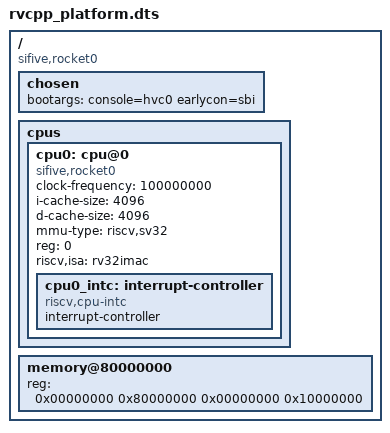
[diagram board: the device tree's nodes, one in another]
/dts-v1/;
/ {
	#address-cells = <2>;
	#size-cells = <2>;
	/* Incantation passed down from the ancient wizards: */
	compatible = "sifive,rocket0", "riscv";

	chosen {
                bootargs = "console=hvc0 earlycon=sbi";
	};

	cpus {
		#address-cells = <1>;
		#size-cells = <0>;
		cpu0: cpu@0 {
			device_type = "cpu";
			compatible = "sifive,rocket0", "riscv";
			clock-frequency = <100000000>;
			i-cache-size = <4096>;
			d-cache-size = <4096>;
			mmu-type = "riscv,sv32";
			reg = <0>;
			riscv,isa = "rv32imac";
			status = "okay";

			/* Think this is just the standard sie/sip controls etc: */
			cpu0_intc: interrupt-controller {
				#interrupt-cells = <1>;
				compatible = "riscv,cpu-intc";
				interrupt-controller;
			};
		};
	};

	memory@80000000 {
		/* Configure 256 MiB of memory */
		device_type = "memory";
		reg = <0x00000000 0x80000000 0x00000000 0x10000000>;
	};

	/* TODO PLIC support in tb
	plic0: interrupt-controller@C000000 {
		#interrupt-cells = <1>;
		compatible = "riscv,plic0";
		interrupt-controller;
		interrupts-extended =
			<&cpu0_intc 11 &cpu0_intc 9
			 &cpu1_intc 11 &cpu1_intc 9>;
		reg = <0x0 0xc000000 0x0 0x4000000>;
	};*/

};
